VERSION ""

NS_ :

BS_:

BU_:

BO_ 1330 update_data_message: 8 Vector__XXX
 SG_ message_type M : 0|8@1+ (1,0) [0|0] "" Vector__XXX
 SG_ update_length m0 : 8|32@1+ (1,0) [0|0] "" Vector__XXX
 SG_ update_md5 m2 : 16|32@1+ (1,0) [0|0] "" Vector__XXX
 SG_ data_block_index m1 : 8|24@1+ (1,0) [0|0] "" Vector__XXX
 SG_ update_data m1 : 32|32@1+ (1,0) [0|0] "" Vector__XXX
 SG_ update_md5_idx m2 : 8|8@1+ (1,0) [0|0] "" Vector__XXX

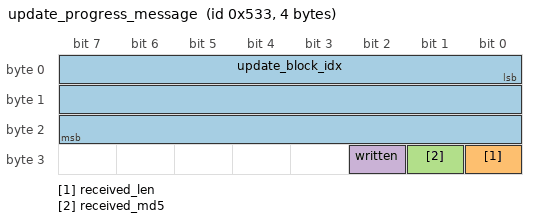
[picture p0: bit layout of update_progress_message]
BO_ 1331 update_progress_message: 4 Vector__XXX
 SG_ update_block_idx : 0|24@1+ (1,0) [0|0] "" Vector__XXX
 SG_ received_len : 24|1@1+ (1,0) [0|0] "" Vector__XXX
 SG_ received_md5 : 25|1@1+ (1,0) [0|0] "" Vector__XXX
 SG_ written : 26|1@1+ (1,0) [0|0] "" Vector__XXX

VAL_ 1330 message_type 0 "UpdateStart" 1 "UpdateData" 2 "Md5" ;
